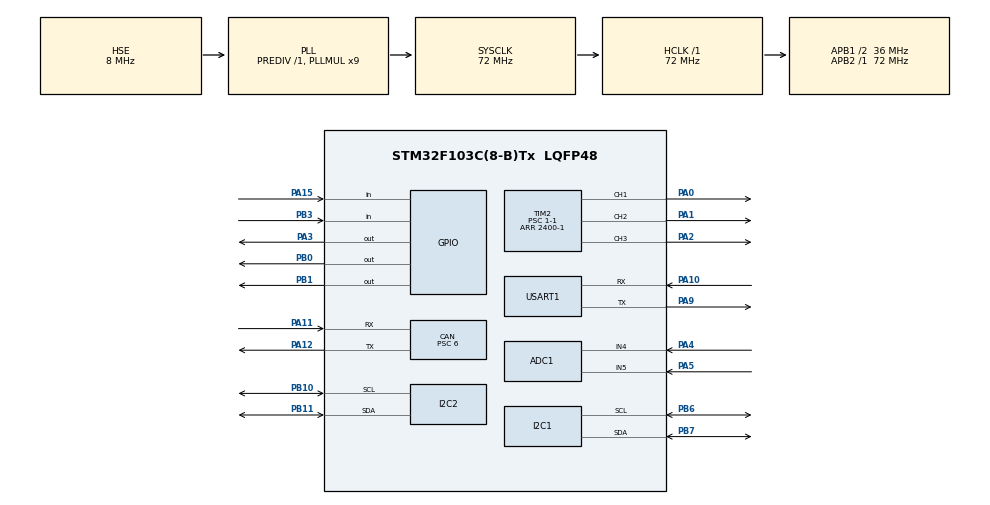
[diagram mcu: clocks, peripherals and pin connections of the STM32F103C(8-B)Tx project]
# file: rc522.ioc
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ADC1.Channel-0\#ChannelRegularConversion=ADC_CHANNEL_4
ADC1.Channel-1\#ChannelRegularConversion=ADC_CHANNEL_5
ADC1.ContinuousConvMode=ENABLE
ADC1.DataAlign=ADC_DATAALIGN_RIGHT
ADC1.NbrOfConversion=2
ADC1.NbrOfConversionFlag=1
ADC1.Rank-0\#ChannelRegularConversion=1
ADC1.Rank-1\#ChannelRegularConversion=2
ADC1.SamplingTime-0\#ChannelRegularConversion=ADC_SAMPLETIME_239CYCLES_5
ADC1.SamplingTime-1\#ChannelRegularConversion=ADC_SAMPLETIME_239CYCLES_5
ADC1.master=1
CAN.BS1=CAN_BS1_8TQ
CAN.BS2=CAN_BS2_3TQ
CAN.CalculateBaudRate=499999
CAN.CalculateTimeBit=2000
CAN.CalculateTimeQuantum=166.66666666666669
CAN.Prescaler=6
Dma.ADC1.1.Direction=DMA_PERIPH_TO_MEMORY
Dma.ADC1.1.Instance=DMA1_Channel1
Dma.ADC1.1.MemDataAlignment=DMA_MDATAALIGN_HALFWORD
Dma.ADC1.1.MemInc=DMA_MINC_ENABLE
Dma.ADC1.1.Mode=DMA_CIRCULAR
Dma.ADC1.1.PeriphDataAlignment=DMA_PDATAALIGN_HALFWORD
Dma.ADC1.1.PeriphInc=DMA_PINC_DISABLE
Dma.ADC1.1.Priority=DMA_PRIORITY_LOW
Dma.Request0=USART1_RX
Dma.Request1=ADC1
Dma.USART1_RX.0.Direction=DMA_PERIPH_TO_MEMORY
Dma.USART1_RX.0.Instance=DMA1_Channel5
Dma.USART1_RX.0.MemDataAlignment=DMA_MDATAALIGN_BYTE
Dma.USART1_RX.0.MemInc=DMA_MINC_ENABLE
Dma.USART1_RX.0.Mode=DMA_NORMAL
Dma.USART1_RX.0.PeriphDataAlignment=DMA_PDATAALIGN_BYTE
Dma.USART1_RX.0.PeriphInc=DMA_PINC_DISABLE
Dma.USART1_RX.0.Priority=DMA_PRIORITY_LOW
I2C1.I2C_Mode=I2C_Fast
Mcu.Family=STM32F1
Mcu.Name=STM32F103C(8-B)Tx
Mcu.Package=LQFP48
NVIC.DMA1_Channel5_IRQn=true\:2\:0\:true\:false\:true\:false\:true\:true
NVIC.PriorityGroup=NVIC_PRIORITYGROUP_4
NVIC.TIM4_IRQn=true\:0\:0\:false\:false\:true\:true\:true\:true
NVIC.USART1_IRQn=true\:2\:0\:true\:false\:true\:true\:true\:true
NVIC.USB_LP_CAN1_RX0_IRQn=true\:0\:0\:false\:false\:true\:true\:true\:true
PA0-WKUP.Signal=S_TIM2_CH1_ETR
PA1.Signal=S_TIM2_CH2
PA10.Mode=Asynchronous
PA10.Signal=USART1_RX
PA11.Mode=CAN_Activate
PA11.Signal=CAN_RX
PA12.Mode=CAN_Activate
PA12.Signal=CAN_TX
PA13.Mode=Serial_Wire
PA13.Signal=SYS_JTMS-SWDIO
PA14.Mode=Serial_Wire
PA14.Signal=SYS_JTCK-SWCLK
PA15.Signal=GPIO_Input
PA2.Signal=S_TIM2_CH3
PA3.Signal=GPIO_Output
PA4.Signal=ADCx_IN4
PA5.Signal=ADCx_IN5
PA9.Mode=Asynchronous
PA9.Signal=USART1_TX
PB0.Signal=GPIO_Output
PB1.Signal=GPIO_Output
PB10.Mode=I2C
PB10.Signal=I2C2_SCL
PB11.Mode=I2C
PB11.Signal=I2C2_SDA
PB3.Signal=GPIO_Input
PB6.Mode=I2C
PB6.Signal=I2C1_SCL
PB7.Mode=I2C
PB7.Signal=I2C1_SDA
PD0-OSC_IN.Mode=HSE-External-Oscillator
PD0-OSC_IN.Signal=RCC_OSC_IN
PD1-OSC_OUT.Mode=HSE-External-Oscillator
PD1-OSC_OUT.Signal=RCC_OSC_OUT
ProjectManager.HeapSize=0x200
ProjectManager.StackSize=0x400
ProjectManager.TargetToolchain=MDK-ARM V5.32
RCC.ADCPresc=RCC_ADCPCLK2_DIV6
RCC.AHBFreq_Value=72000000
RCC.APB1CLKDivider=RCC_HCLK_DIV2
RCC.APB1Freq_Value=36000000
RCC.APB1TimFreq_Value=72000000
RCC.APB2Freq_Value=72000000
RCC.APB2TimFreq_Value=72000000
RCC.HCLKFreq_Value=72000000
RCC.PLLMUL=RCC_PLL_MUL9
RCC.PLLSourceVirtual=RCC_PLLSOURCE_HSE
RCC.SYSCLKFreq_VALUE=72000000
RCC.SYSCLKSource=RCC_SYSCLKSOURCE_PLLCLK
RCC.USBFreq_Value=72000000
SH.ADCx_IN4.0=ADC1_IN4,IN4
SH.ADCx_IN5.0=ADC1_IN5,IN5
SH.S_TIM2_CH1_ETR.0=TIM2_CH1,PWM Generation1 CH1
SH.S_TIM2_CH2.0=TIM2_CH2,PWM Generation2 CH2
SH.S_TIM2_CH3.0=TIM2_CH3,PWM Generation3 CH3
TIM2.Channel-PWM\ Generation1\ CH1=TIM_CHANNEL_1
TIM2.Channel-PWM\ Generation2\ CH2=TIM_CHANNEL_2
TIM2.Channel-PWM\ Generation3\ CH3=TIM_CHANNEL_3
TIM2.CounterMode=TIM_COUNTERMODE_CENTERALIGNED1
TIM2.Period=2400-1
TIM2.Prescaler=1-1
TIM4.Period=1000-1
TIM4.Prescaler=72-1
USART1.VirtualMode=VM_ASYNC
VP_TIM2_VS_ClockSourceINT.Mode=Internal
VP_TIM4_VS_ClockSourceINT.Mode=Internal
board=custom

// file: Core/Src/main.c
/* USER CODE BEGIN Header */
/**
  ******************************************************************************
  * @file           : main.c
  * @brief          : Main program body
  ******************************************************************************
  * @attention
  *
  * Copyright (c) 2025 STMicroelectronics.
  * All rights reserved.
  *
  * This software is licensed under terms that can be found in the LICENSE file
  * in the root directory of this software component.
  * If no LICENSE file comes with this software, it is provided AS-IS.
  *
  ******************************************************************************
  */
/* USER CODE END Header */
#include "main.h"
#include "adc.h"
#include "can.h"
#include "dma.h"
#include "i2c.h"
#include "tim.h"
#include "usart.h"
#include "gpio.h"

/* USER CODE BEGIN Includes */

#include "bsp_system.h"

/* USER CODE END Includes */

void SystemClock_Config(void);

/* USER CODE BEGIN 0 */
uint8_t jishu = 0;
/* USER CODE END 0 */

int main(void)
{

  /* MCU Configuration--------------------------------------------------------*/

  /* Reset of all peripherals, Initializes the Flash interface and the Systick. */
  HAL_Init();

  /* Configure the system clock */
  SystemClock_Config();

  /* USER CODE BEGIN SysInit */

I2C_Bus_Reset(GPIOB, GPIO_PIN_6, GPIOB, GPIO_PIN_7);//这个地方是指复位一下IIC，这个需要放在MX_I2C2_Init前面，如果在MX_I2C2_Init后面就会导致该引脚变为普通IO口引脚
  /* USER CODE END SysInit */

  /* Initialize all configured peripherals */
  MX_GPIO_Init();
  MX_DMA_Init();
  MX_USART1_UART_Init();
  MX_I2C1_Init();
  MX_I2C2_Init();
  MX_TIM2_Init();
  MX_TIM4_Init();
  MX_ADC1_Init();
  MX_CAN_Init();
  /* USER CODE BEGIN 2 */

//====================模块初始化==================

	 //oled_init();

//================================================

	// 2. 显式清除一下 USART2 的潜在错误标志 (ORE/FE)
	// 直接操作寄存器清除状态，确保干净启动
//	__HAL_UART_CLEAR_OREFLAG(&huart2);
//	__HAL_UART_CLEAR_NEFLAG(&huart2);
//	__HAL_UART_CLEAR_FEFLAG(&huart2);
//	__HAL_UART_CLEAR_IDLEFLAG(&huart2);
//	HAL_UARTEx_ReceiveToIdle_DMA(&huart2, uart2_rx_buff, sizeof(uart2_rx_buff));
//
//	__HAL_UART_CLEAR_OREFLAG(&huart3);
//	__HAL_UART_CLEAR_NEFLAG(&huart3);
//	__HAL_UART_CLEAR_FEFLAG(&huart3);
//	__HAL_UART_CLEAR_IDLEFLAG(&huart3);
//	HAL_UARTEx_ReceiveToIdle_DMA(&huart3, uart3_rx_buff, sizeof(uart3_rx_buff));

	init_all();

  /* USER CODE END 2 */

  /* Infinite loop */
  while (1)
  {

    /* USER CODE BEGIN 3 */

//		uart_proc();
//		Set_Velocity(1);  // motor1

		// move(1);
		// loopFOC();
		//任务执行
		scheduler_run();

#if (CALIBRATION_MODE == 2)
		/* 处理按键校准请求（非阻塞） */
		Calibration_Process();
#endif

  }
  /* USER CODE END 3 */
}

void SystemClock_Config(void)
{
  RCC_OscInitTypeDef RCC_OscInitStruct = {0};
  RCC_ClkInitTypeDef RCC_ClkInitStruct = {0};
  RCC_PeriphCLKInitTypeDef PeriphClkInit = {0};

  /** Initializes the RCC Oscillators according to the specified parameters
  * in the RCC_OscInitTypeDef structure.
  */
  RCC_OscInitStruct.OscillatorType = RCC_OSCILLATORTYPE_HSE;
  RCC_OscInitStruct.HSEState = RCC_HSE_ON;
  RCC_OscInitStruct.HSEPredivValue = RCC_HSE_PREDIV_DIV1;
  RCC_OscInitStruct.HSIState = RCC_HSI_ON;
  RCC_OscInitStruct.PLL.PLLState = RCC_PLL_ON;
  RCC_OscInitStruct.PLL.PLLSource = RCC_PLLSOURCE_HSE;
  RCC_OscInitStruct.PLL.PLLMUL = RCC_PLL_MUL9;
  if (HAL_RCC_OscConfig(&RCC_OscInitStruct) != HAL_OK)
  {
    Error_Handler();
  }

  /** Initializes the CPU, AHB and APB buses clocks
  */
  RCC_ClkInitStruct.ClockType = RCC_CLOCKTYPE_HCLK|RCC_CLOCKTYPE_SYSCLK
                              |RCC_CLOCKTYPE_PCLK1|RCC_CLOCKTYPE_PCLK2;
  RCC_ClkInitStruct.SYSCLKSource = RCC_SYSCLKSOURCE_PLLCLK;
  RCC_ClkInitStruct.AHBCLKDivider = RCC_SYSCLK_DIV1;
  RCC_ClkInitStruct.APB1CLKDivider = RCC_HCLK_DIV2;
  RCC_ClkInitStruct.APB2CLKDivider = RCC_HCLK_DIV1;

  if (HAL_RCC_ClockConfig(&RCC_ClkInitStruct, FLASH_LATENCY_2) != HAL_OK)
  {
    Error_Handler();
  }
  PeriphClkInit.PeriphClockSelection = RCC_PERIPHCLK_ADC;
  PeriphClkInit.AdcClockSelection = RCC_ADCPCLK2_DIV6;
  if (HAL_RCCEx_PeriphCLKConfig(&PeriphClkInit) != HAL_OK)
  {
    Error_Handler();
  }
}

void Error_Handler(void)
{
  __disable_irq();
  while (1)
  {
  }
}
